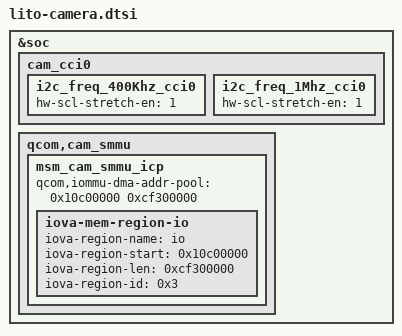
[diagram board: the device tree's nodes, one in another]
#include <dt-bindings/msm/msm-camera.h>

&soc {
	cam_cci0 {
		i2c_freq_400Khz_cci0 {
			/*#ifdef VENDOR_EDIT*/
			/*add by yufeng@camera 20190730*/
			hw-scl-stretch-en = <1>;
			/*#else*/
			//hw-scl-stretch-en = <0>;
			/*#endif*/
		};
		i2c_freq_1Mhz_cci0 {

		    /*#ifdef VENDOR_EDIT*/
			/*add by yufeng@camera 20190730*/
			hw-scl-stretch-en = <1>;
			/*#else*/
			//hw-scl-stretch-en = <0>;
			/*#endif*/
		};
	};
	qcom,cam_smmu {
		msm_cam_smmu_icp {
			/* suraj.chennoji@Camera, CSLALLOCHW crash issue, Corrected the address
			mapping for dma addr pool for icp which caused, QC Case#04275326*/
			/* qcom,iommu-dma-addr-pool = <0xda00000 0xace00000>; */
			qcom,iommu-dma-addr-pool = <0x10c00000 0xcf300000>;

			iova-mem-region-io {
				/* IO region is approximately 3.3 GB */
				iova-region-name = "io";
				iova-region-start = <0x10c00000>;
				iova-region-len = <0xcf300000>;
				iova-region-id = <0x3>;
				status = "ok";
			};
		};
	};
};
